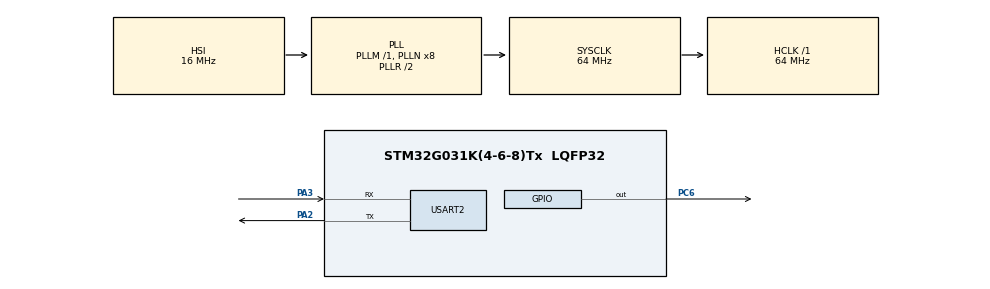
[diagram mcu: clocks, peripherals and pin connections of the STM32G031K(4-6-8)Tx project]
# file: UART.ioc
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Mcu.Family=STM32G0
RCC.CortexFreq_Value=64000000
PC6.Signal=GPIO_Output
RCC.EXTERNAL_CLOCK_VALUE=12288000
NVIC.USART2_IRQn=true\:0\:0\:false\:false\:true\:true\:true
RCC.SYSCLKSource=RCC_SYSCLKSOURCE_PLLCLK
ProjectManager.StackSize=0x400
PA3.Mode=Asynchronous
ProjectManager.TargetToolchain=STM32CubeIDE
RCC.HCLKFreq_Value=64000000
RCC.LSE_VALUE=32768
RCC.AHBFreq_Value=64000000
RCC.HSE_VALUE=8000000
board=custom
USART2.VirtualMode-Asynchronous=VM_ASYNC
RCC.VCOOutputFreq_Value=128000000
RCC.ADCFreq_Value=64000000
Mcu.Name=STM32G031K(4-6-8)Tx
PA2.Signal=USART2_TX
RCC.SYSCLKFreq_VALUE=64000000
Mcu.Package=LQFP32
ProjectManager.HeapSize=0x200
RCC.HSI_VALUE=16000000
PA2.Mode=Asynchronous
PA3.Signal=USART2_RX

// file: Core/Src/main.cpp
/* USER CODE BEGIN Header */
/**
  ******************************************************************************
  * @file           : main.c
  * @brief          : Main program body
  ******************************************************************************
  * @attention
  *
  * <h2><center>&copy; Copyright (c) 2022 STMicroelectronics.
  * All rights reserved.</center></h2>
  *
  * This software component is licensed by ST under BSD 3-Clause license,
  * the "License"; You may not use this file except in compliance with the
  * License. You may obtain a copy of the License at:
  *                        opensource.org/licenses/BSD-3-Clause
  *
  ******************************************************************************
  */
/* USER CODE END Header */
#include "main.h"
#include <string>
#include <stdio.h>
#include <string.h>
using namespace std;

#define Led_ON() HAL_GPIO_WritePin(GPIOC, GPIO_PIN_6, GPIO_PIN_SET)
#define Led_OFF() HAL_GPIO_WritePin(GPIOC, GPIO_PIN_6, GPIO_PIN_RESET)
#define Led_TOGGLE() HAL_GPIO_TogglePin(GPIOC, GPIO_PIN_6)
/* USER CODE BEGIN Includes*/

/* USER CODE END Includes*/

UART_HandleTypeDef huart2;
char tx_arr[10];
uint8_t RS232_rx_flag = 0;	//Flag to check Uart interrupt
char RS232_rxbuffer[10];	//Buffer to store Uart Data
string str_rx;
//Interrupt Service Routine
void HAL_UART_RxCpltCallback(UART_HandleTypeDef *huart)
{
 if(huart->Instance==USART2)
 {
	 RS232_rx_flag = 1;
 }
}

//Functions to send data on uart using UART2 with String
//Also Function Overloading is used for uart_tx functions
void uart_tx(string str)
{
	char *tx_ptr = new char[str.length() + 1];
	strcpy(tx_ptr, str.c_str());
	HAL_UART_Transmit(&huart2, (uint8_t *)tx_ptr, strlen(tx_ptr), HAL_MAX_DELAY);
	delete tx_ptr;
}

void uart_tx(double var)
{
	sprintf(tx_arr, "%0.3f", var);
	uart_tx(tx_arr);
}

void uart_tx(int var)
{
	sprintf(tx_arr, "%d", var);
	uart_tx(tx_arr);
}

void SystemClock_Config(void);
static void MX_GPIO_Init(void);
static void MX_USART2_UART_Init(void);

int main(void)
{
  /* MCU Configuration--------------------------------------------------------*/
  /* Reset of all peripherals, Initializes the Flash interface and the Systick. */
  HAL_Init();
  /* Configure the system clock */
  SystemClock_Config();
  /* Initialize all configured peripherals */
  MX_GPIO_Init();
  MX_USART2_UART_Init();
  /* USER CODE BEGIN 2 */
  uart_tx("Testing of Uart Reception using Interrupt....\n\r");
  uart_tx("For testing 3 commands to be used...\n\r");
  uart_tx("Command1 :> 1234567890\n\r");
  uart_tx("Command2 :> 2134567890\n\r");
  uart_tx("Command3 :> 3134567890\n\r");
  uart_tx("Make sure to send 10 characters to be send otherwise controller get stuck\n\r");
  /* USER CODE END 2 */
  HAL_UART_Receive_IT(&huart2, (uint8_t *)RS232_rxbuffer, 10);	//Enable Uart Reception in Interrupt Mode with 10 bytes

  /* Infinite loop */
  while (1)
  {
	  if (RS232_rx_flag == 1)
	  {
		  str_rx = RS232_rxbuffer;
		  if (str_rx.compare("1234567890") == 0)uart_tx("Case 1 command Received\n\r");
		  else if(str_rx.compare("2134567890") == 0)uart_tx("Case 2 command Received\n\r");
		  else if(str_rx.compare("3134567890") == 0)uart_tx("Case 3 command Received\n\r");
		  else uart_tx("Incorrect command, Send proper command\n\r");
		  RS232_rx_flag = 0;												//Clearing Flag to use interrupt again
		  HAL_UART_Receive_IT(&huart2, (uint8_t *)RS232_rxbuffer, 10);		//Enabling Uart interrupt again
	  }
	  Led_TOGGLE();
	  HAL_Delay(1000);
  }
}

void SystemClock_Config(void)
{
  RCC_OscInitTypeDef RCC_OscInitStruct = {0};
  RCC_ClkInitTypeDef RCC_ClkInitStruct = {0};

  /** Configure the main internal regulator output voltage
  */
  HAL_PWREx_ControlVoltageScaling(PWR_REGULATOR_VOLTAGE_SCALE1);
  /** Initializes the RCC Oscillators according to the specified parameters
  * in the RCC_OscInitTypeDef structure.
  */
  RCC_OscInitStruct.OscillatorType = RCC_OSCILLATORTYPE_HSI;
  RCC_OscInitStruct.HSIState = RCC_HSI_ON;
  RCC_OscInitStruct.HSIDiv = RCC_HSI_DIV1;
  RCC_OscInitStruct.HSICalibrationValue = RCC_HSICALIBRATION_DEFAULT;
  RCC_OscInitStruct.PLL.PLLState = RCC_PLL_ON;
  RCC_OscInitStruct.PLL.PLLSource = RCC_PLLSOURCE_HSI;
  RCC_OscInitStruct.PLL.PLLM = RCC_PLLM_DIV1;
  RCC_OscInitStruct.PLL.PLLN = 8;
  RCC_OscInitStruct.PLL.PLLP = RCC_PLLP_DIV2;
  RCC_OscInitStruct.PLL.PLLQ = RCC_PLLQ_DIV2;
  RCC_OscInitStruct.PLL.PLLR = RCC_PLLR_DIV2;
  if (HAL_RCC_OscConfig(&RCC_OscInitStruct) != HAL_OK)
  {
    Error_Handler();
  }
  /** Initializes the CPU, AHB and APB buses clocks
  */
  RCC_ClkInitStruct.ClockType = RCC_CLOCKTYPE_HCLK|RCC_CLOCKTYPE_SYSCLK
                              |RCC_CLOCKTYPE_PCLK1;
  RCC_ClkInitStruct.SYSCLKSource = RCC_SYSCLKSOURCE_PLLCLK;
  RCC_ClkInitStruct.AHBCLKDivider = RCC_SYSCLK_DIV1;
  RCC_ClkInitStruct.APB1CLKDivider = RCC_HCLK_DIV1;

  if (HAL_RCC_ClockConfig(&RCC_ClkInitStruct, FLASH_LATENCY_2) != HAL_OK)
  {
    Error_Handler();
  }
}

static void MX_USART2_UART_Init(void)
{

  huart2.Instance = USART2;
  huart2.Init.BaudRate = 115200;
  huart2.Init.WordLength = UART_WORDLENGTH_8B;
  huart2.Init.StopBits = UART_STOPBITS_1;
  huart2.Init.Parity = UART_PARITY_NONE;
  huart2.Init.Mode = UART_MODE_TX_RX;
  huart2.Init.HwFlowCtl = UART_HWCONTROL_NONE;
  huart2.Init.OverSampling = UART_OVERSAMPLING_16;
  huart2.Init.OneBitSampling = UART_ONE_BIT_SAMPLE_DISABLE;
  huart2.Init.ClockPrescaler = UART_PRESCALER_DIV1;
  huart2.AdvancedInit.AdvFeatureInit = UART_ADVFEATURE_NO_INIT;
  if (HAL_UART_Init(&huart2) != HAL_OK)
  {
    Error_Handler();
  }

}

static void MX_GPIO_Init(void)
{
  GPIO_InitTypeDef GPIO_InitStruct = {0};

  /* GPIO Ports Clock Enable */
  __HAL_RCC_GPIOA_CLK_ENABLE();
  __HAL_RCC_GPIOC_CLK_ENABLE();

  /*Configure GPIO pin Output Level */
  HAL_GPIO_WritePin(GPIOC, GPIO_PIN_6, GPIO_PIN_RESET);

  /*Configure GPIO pin : PC6 */
  GPIO_InitStruct.Pin = GPIO_PIN_6;
  GPIO_InitStruct.Mode = GPIO_MODE_OUTPUT_PP;
  GPIO_InitStruct.Pull = GPIO_NOPULL;
  GPIO_InitStruct.Speed = GPIO_SPEED_FREQ_LOW;
  HAL_GPIO_Init(GPIOC, &GPIO_InitStruct);

}

void Error_Handler(void)
{
  __disable_irq();
  while (1)
  {
  }
}

/************************ (C) COPYRIGHT STMicroelectronics *****END OF FILE****/
